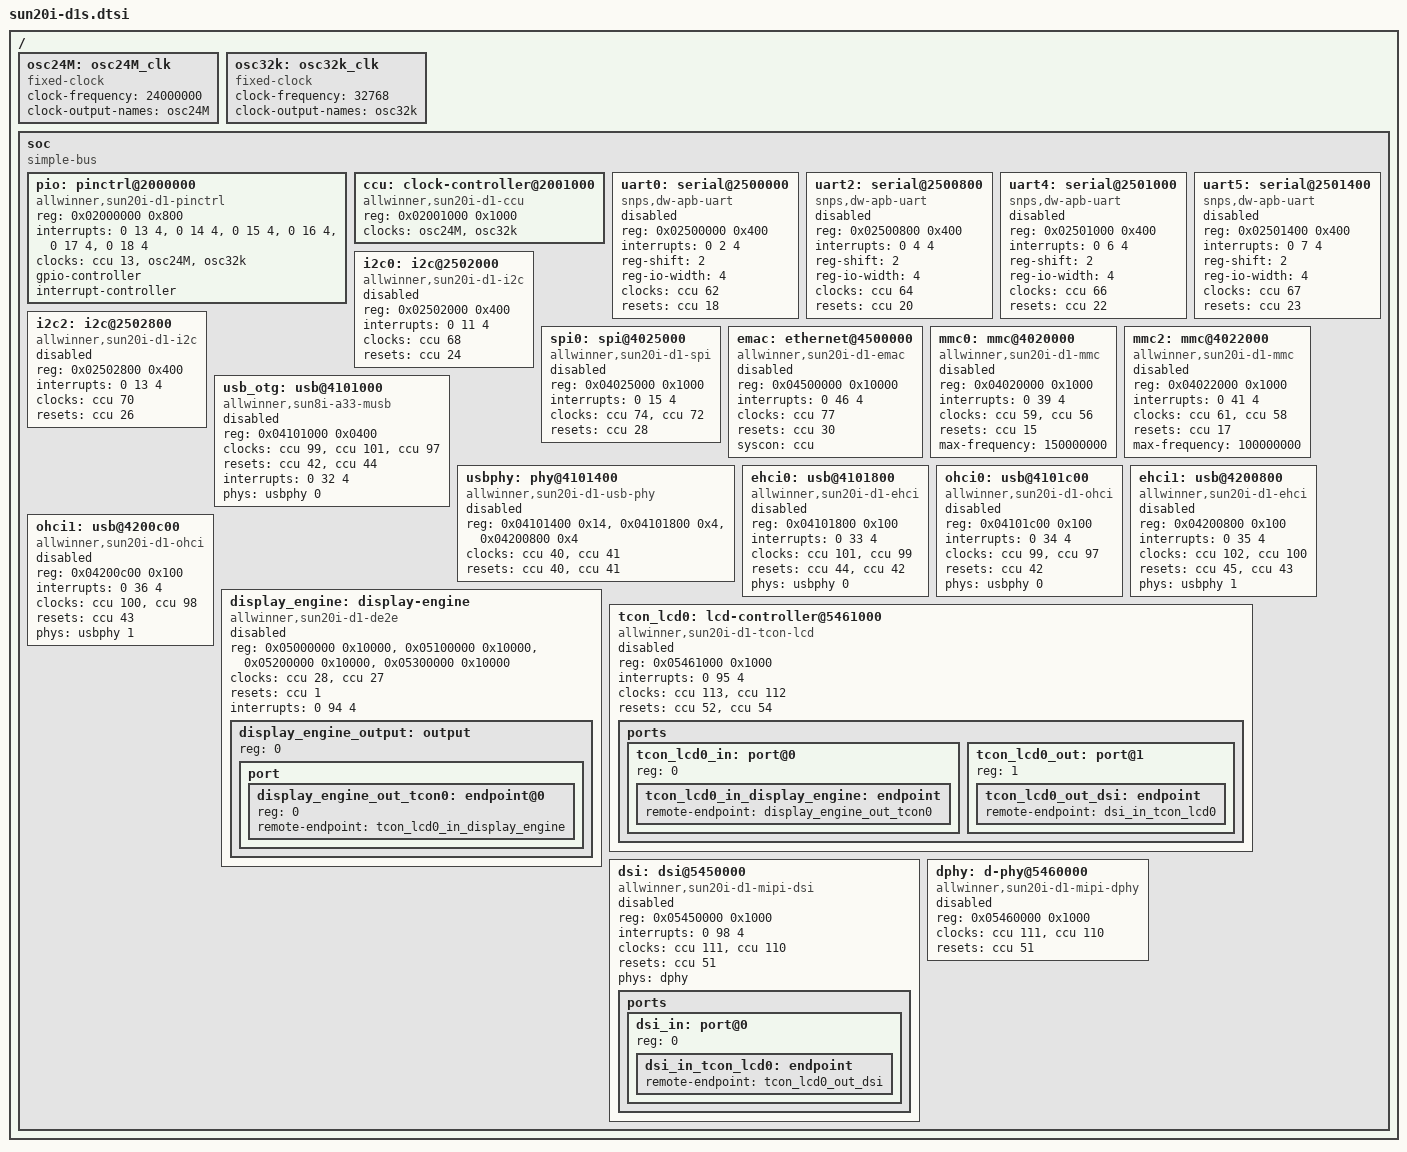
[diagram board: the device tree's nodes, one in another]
// SPDX-License-Identifier: (GPL-2.0+ OR MIT)
/* 纯数字硬编码版 - 无需任何头文件 */

/ {
	osc24M: osc24M_clk {
		#clock-cells = <0>;
		compatible = "fixed-clock";
		clock-frequency = <24000000>;
		clock-output-names = "osc24M";
	};

	osc32k: osc32k_clk {
		#clock-cells = <0>;
		compatible = "fixed-clock";
		clock-frequency = <32768>;
		clock-output-names = "osc32k";
	};

	soc {
		#address-cells = <1>;
		#size-cells = <1>;
		compatible = "simple-bus";
		ranges;

		pio: pinctrl@2000000 {
			compatible = "allwinner,sun20i-d1-pinctrl";
			reg = <0x02000000 0x800>;
			/* GIC_SPI=0, IRQ_TYPE_LEVEL_HIGH=4 */
			interrupts = <0 13 4>, <0 14 4>, <0 15 4>, <0 16 4>, <0 17 4>, <0 18 4>;
			/* CLK_APB1=13, CLK_LOSC=0 (placeholder) */
			clocks = <&ccu 13>, <&osc24M>, <&osc32k>;
			clock-names = "apb", "hosc", "losc";
			gpio-controller;
			#gpio-cells = <3>;
			interrupt-controller;
			#interrupt-cells = <3>;
		};

		ccu: clock-controller@2001000 {
			compatible = "allwinner,sun20i-d1-ccu";
			reg = <0x02001000 0x1000>;
			clocks = <&osc24M>, <&osc32k>;
			clock-names = "hosc", "losc";
			#clock-cells = <1>;
			#reset-cells = <1>;
		};

		uart0: serial@2500000 {
			compatible = "snps,dw-apb-uart";
			reg = <0x02500000 0x400>;
			interrupts = <0 2 4>;
			reg-shift = <2>;
			reg-io-width = <4>;
			clocks = <&ccu 62>; /* CLK_BUS_UART0 */
			resets = <&ccu 18>; /* RST_BUS_UART0 */
			status = "disabled";
		};

		uart2: serial@2500800 {
			compatible = "snps,dw-apb-uart";
			reg = <0x02500800 0x400>;
			interrupts = <0 4 4>;
			reg-shift = <2>;
			reg-io-width = <4>;
			clocks = <&ccu 64>;
			resets = <&ccu 20>;
			status = "disabled";
		};

		uart4: serial@2501000 {
			compatible = "snps,dw-apb-uart";
			reg = <0x02501000 0x400>;
			interrupts = <0 6 4>;
			reg-shift = <2>;
			reg-io-width = <4>;
			clocks = <&ccu 66>;
			resets = <&ccu 22>;
			status = "disabled";
		};

		uart5: serial@2501400 {
			compatible = "snps,dw-apb-uart";
			reg = <0x02501400 0x400>;
			interrupts = <0 7 4>;
			reg-shift = <2>;
			reg-io-width = <4>;
			clocks = <&ccu 67>;
			resets = <&ccu 23>;
			status = "disabled";
		};

		i2c0: i2c@2502000 {
			compatible = "allwinner,sun20i-d1-i2c", "allwinner,sun8i-v536-i2c";
			reg = <0x02502000 0x400>;
			interrupts = <0 11 4>;
			clocks = <&ccu 68>;
			resets = <&ccu 24>;
			#address-cells = <1>;
			#size-cells = <0>;
			status = "disabled";
		};

		i2c2: i2c@2502800 {
			compatible = "allwinner,sun20i-d1-i2c", "allwinner,sun8i-v536-i2c";
			reg = <0x02502800 0x400>;
			interrupts = <0 13 4>;
			clocks = <&ccu 70>;
			resets = <&ccu 26>;
			#address-cells = <1>;
			#size-cells = <0>;
			status = "disabled";
		};

		spi0: spi@4025000 {
			compatible = "allwinner,sun20i-d1-spi", "allwinner,sun8i-h3-spi";
			reg = <0x04025000 0x1000>;
			interrupts = <0 15 4>;
			clocks = <&ccu 74>, <&ccu 72>; /* BUS_SPI0, SPI0 */
			clock-names = "ahb", "mod";
			resets = <&ccu 28>;
			status = "disabled";
			#address-cells = <1>;
			#size-cells = <0>;
		};

		emac: ethernet@4500000 {
			compatible = "allwinner,sun20i-d1-emac", "allwinner,sun8i-a83t-emac";
			reg = <0x04500000 0x10000>;
			interrupts = <0 46 4>;
			interrupt-names = "macirq";
			clocks = <&ccu 77>;
			clock-names = "stmmaceth";
			resets = <&ccu 30>;
			reset-names = "stmmaceth";
			syscon = <&ccu>;
			status = "disabled";
		};

		mmc0: mmc@4020000 {
			compatible = "allwinner,sun20i-d1-mmc", "allwinner,sun7i-a20-mmc";
			reg = <0x04020000 0x1000>;
			interrupts = <0 39 4>;
			clocks = <&ccu 59>, <&ccu 56>; /* BUS_MMC0, MMC0 */
			clock-names = "ahb", "mmc";
			resets = <&ccu 15>;
			reset-names = "ahb";
			max-frequency = <150000000>;
			status = "disabled";
			#address-cells = <1>;
			#size-cells = <0>;
		};

		mmc2: mmc@4022000 {
			compatible = "allwinner,sun20i-d1-mmc", "allwinner,sun7i-a20-mmc";
			reg = <0x04022000 0x1000>;
			interrupts = <0 41 4>;
			clocks = <&ccu 61>, <&ccu 58>;
			clock-names = "ahb", "mmc";
			resets = <&ccu 17>;
			reset-names = "ahb";
			max-frequency = <100000000>;
			status = "disabled";
			#address-cells = <1>;
			#size-cells = <0>;
		};

		usb_otg: usb@4101000 {
			compatible = "allwinner,sun8i-a33-musb";
			reg = <0x04101000 0x0400>;
			clocks = <&ccu 99>, <&ccu 101>, <&ccu 97>; /* BUS_OHCI0, BUS_EHCI0, USB_OHCI0 */
			resets = <&ccu 42>, <&ccu 44>; /* BUS_OHCI0, BUS_EHCI0 */
			interrupts = <0 32 4>;
			interrupt-names = "mc";
			phys = <&usbphy 0>;
			phy-names = "usb";
			status = "disabled";
		};

		usbphy: phy@4101400 {
			compatible = "allwinner,sun20i-d1-usb-phy";
			reg = <0x04101400 0x14>,
			      <0x04101800 0x4>,
			      <0x04200800 0x4>;
			reg-names = "phy_ctrl", "pmu0", "pmu1";
			clocks = <&ccu 40>, <&ccu 41>; /* USB_PHY0, USB_PHY1 */
			clock-names = "usb0_phy", "usb1_phy";
			resets = <&ccu 40>, <&ccu 41>; /* USB_PHY0, USB_PHY1 */
			reset-names = "usb0_reset", "usb1_reset";
			status = "disabled";
			#phy-cells = <1>;
		};

		ehci0: usb@4101800 {
			compatible = "allwinner,sun20i-d1-ehci", "generic-ehci";
			reg = <0x04101800 0x100>;
			interrupts = <0 33 4>;
			clocks = <&ccu 101>, <&ccu 99>;
			resets = <&ccu 44>, <&ccu 42>;
			phys = <&usbphy 0>;
			phy-names = "usb";
			status = "disabled";
		};

		ohci0: usb@4101c00 {
			compatible = "allwinner,sun20i-d1-ohci", "generic-ohci";
			reg = <0x04101c00 0x100>;
			interrupts = <0 34 4>;
			clocks = <&ccu 99>, <&ccu 97>;
			resets = <&ccu 42>;
			phys = <&usbphy 0>;
			phy-names = "usb";
			status = "disabled";
		};

		ehci1: usb@4200800 {
			compatible = "allwinner,sun20i-d1-ehci", "generic-ehci";
			reg = <0x04200800 0x100>;
			interrupts = <0 35 4>;
			clocks = <&ccu 102>, <&ccu 100>;
			resets = <&ccu 45>, <&ccu 43>;
			phys = <&usbphy 1>;
			phy-names = "usb";
			status = "disabled";
		};

		ohci1: usb@4200c00 {
			compatible = "allwinner,sun20i-d1-ohci", "generic-ohci";
			reg = <0x04200c00 0x100>;
			interrupts = <0 36 4>;
			clocks = <&ccu 100>, <&ccu 98>;
			resets = <&ccu 43>;
			phys = <&usbphy 1>;
			phy-names = "usb";
			status = "disabled";
		};

		display_engine: display-engine {
			compatible = "allwinner,sun20i-d1-de2e";
			reg = <0x05000000 0x10000>,
			      <0x05100000 0x10000>,
			      <0x05200000 0x10000>,
			      <0x05300000 0x10000>;
			reg-names = "blender", "ui", "top", "scaler";
			clocks = <&ccu 28>, <&ccu 27>; /* BUS_DE, DE */
			clock-names = "bus", "mod";
			resets = <&ccu 1>; /* RST_BUS_DE */
			interrupts = <0 94 4>;
			status = "disabled";
			#address-cells = <1>;
			#size-cells = <0>;

			display_engine_output: output {
				reg = <0>;
				port {
					#address-cells = <1>;
					#size-cells = <0>;
					display_engine_out_tcon0: endpoint@0 {
						reg = <0>;
						remote-endpoint = <&tcon_lcd0_in_display_engine>;
					};
				};
			};
		};

		tcon_lcd0: lcd-controller@5461000 {
			compatible = "allwinner,sun20i-d1-tcon-lcd";
			reg = <0x05461000 0x1000>;
			interrupts = <0 95 4>;
			clocks = <&ccu 113>, <&ccu 112>; /* BUS_TCON, TCON */
			clock-names = "ahb", "tcon";
			resets = <&ccu 52>, <&ccu 54>; /* RST_TCON, RST_LVDS */
			reset-names = "lcd", "lvds";
			status = "disabled";

			ports {
				#address-cells = <1>;
				#size-cells = <0>;

				tcon_lcd0_in: port@0 {
					reg = <0>;
					tcon_lcd0_in_display_engine: endpoint {
						remote-endpoint = <&display_engine_out_tcon0>;
					};
				};

				tcon_lcd0_out: port@1 {
					reg = <1>;
					tcon_lcd0_out_dsi: endpoint {
						remote-endpoint = <&dsi_in_tcon_lcd0>;
					};
				};
			};
		};

		dsi: dsi@5450000 {
			compatible = "allwinner,sun20i-d1-mipi-dsi";
			reg = <0x05450000 0x1000>;
			interrupts = <0 98 4>;
			clocks = <&ccu 111>, <&ccu 110>; /* BUS_DSI, DSI */
			clock-names = "bus", "mod";
			resets = <&ccu 51>;
			phys = <&dphy>;
			phy-names = "dphy";
			status = "disabled";

			ports {
				#address-cells = <1>;
				#size-cells = <0>;

				dsi_in: port@0 {
					reg = <0>;
					dsi_in_tcon_lcd0: endpoint {
						remote-endpoint = <&tcon_lcd0_out_dsi>;
					};
				};
			};
		};

		dphy: d-phy@5460000 {
			compatible = "allwinner,sun20i-d1-mipi-dphy";
			reg = <0x05460000 0x1000>;
			clocks = <&ccu 111>, <&ccu 110>;
			clock-names = "bus", "mod";
			resets = <&ccu 51>;
			status = "disabled";
			#phy-cells = <0>;
		};
	};
};
